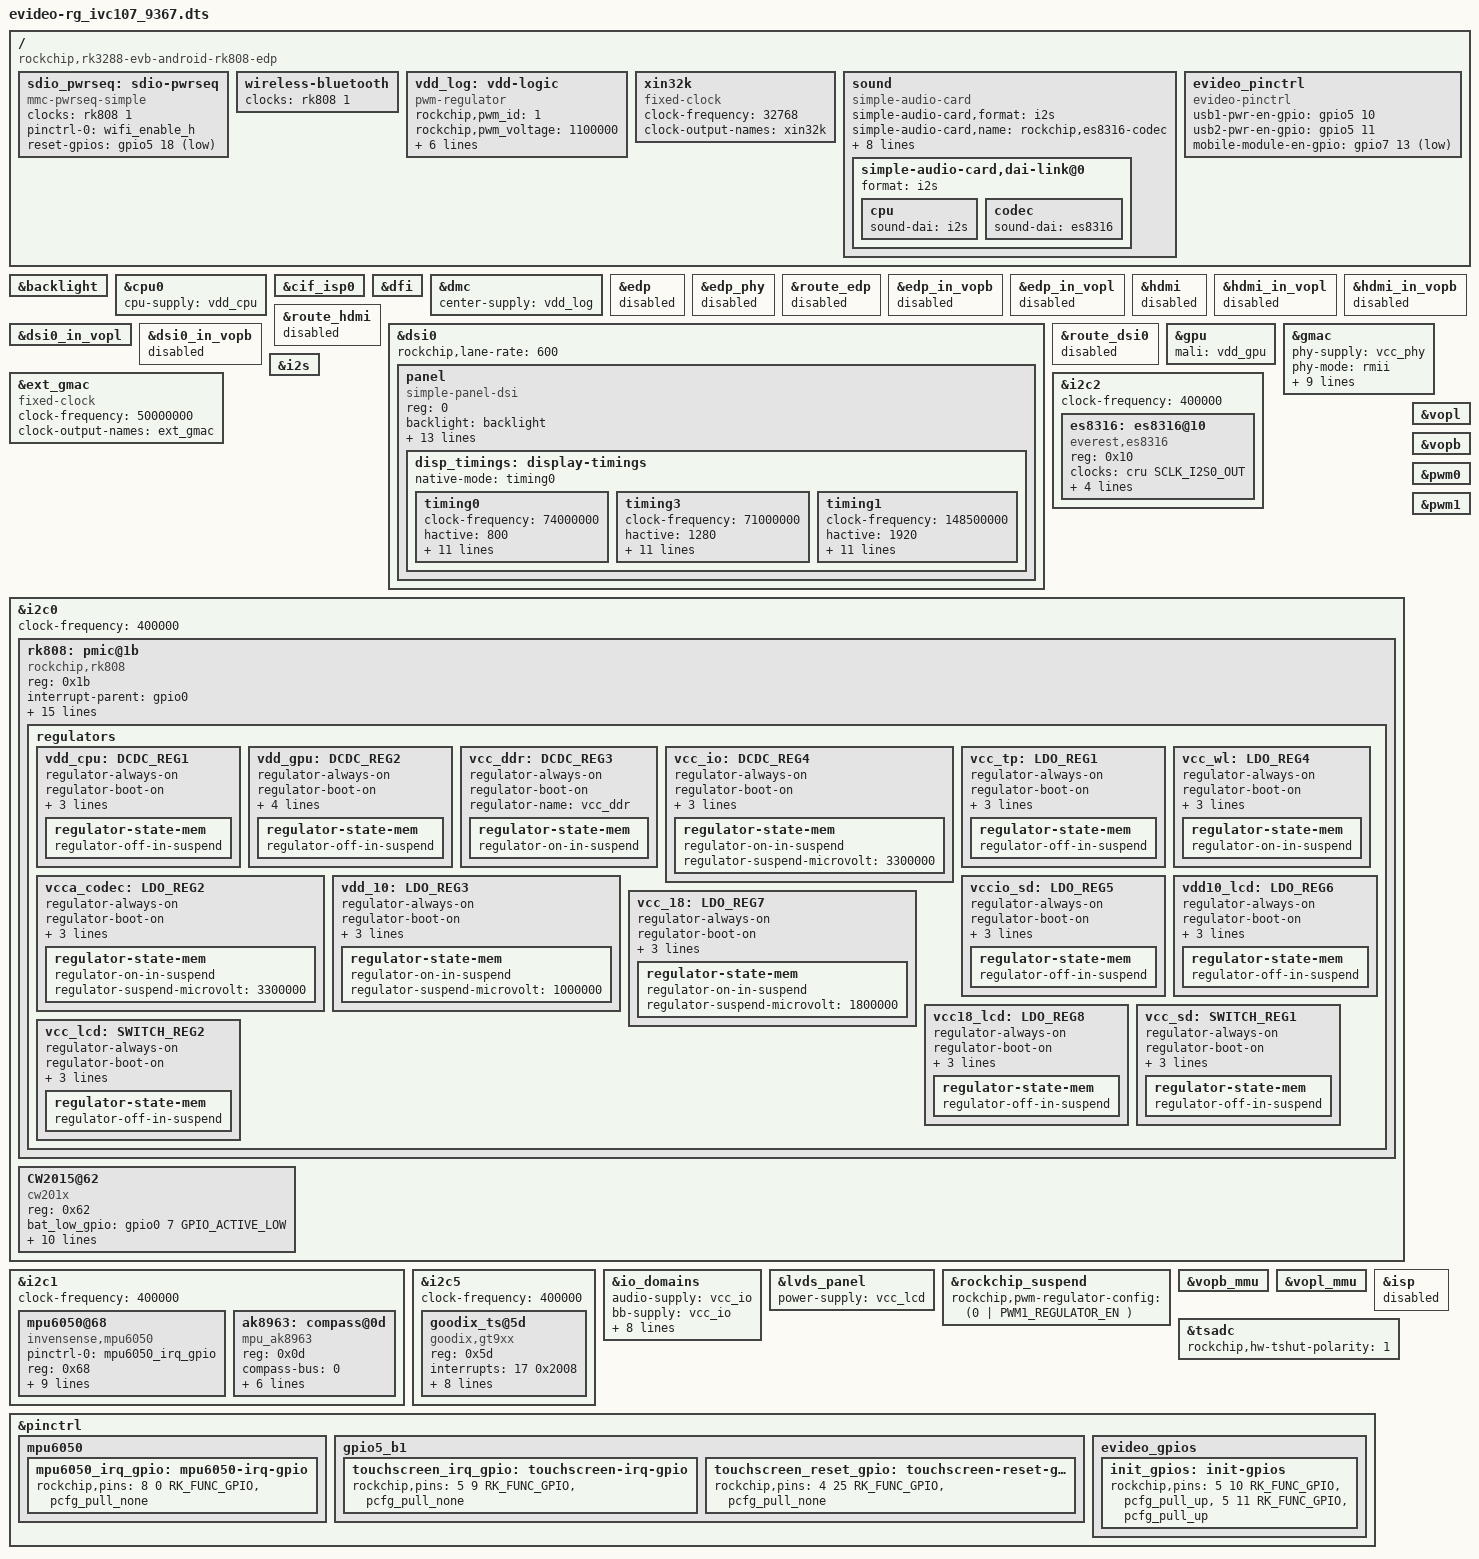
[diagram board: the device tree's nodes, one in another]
/*
 * This file is dual-licensed: you can use it either under the terms
 * of the GPL or the X11 license, at your option. Note that this dual
 * licensing only applies to this file, and not this project as a
 * whole.
 *
 *  a) This file is free software; you can redistribute it and/or
 *     modify it under the terms of the GNU General Public License as
 *     published by the Free Software Foundation; either version 2 of the
 *     License, or (at your option) any later version.
 *
 *     This file is distributed in the hope that it will be useful,
 *     but WITHOUT ANY WARRANTY; without even the implied warranty of
 *     MERCHANTABILITY or FITNESS FOR A PARTICULAR PURPOSE.  See the
 *     GNU General Public License for more details.
 *
 * Or, alternatively,
 *
 *  b) Permission is hereby granted, free of charge, to any person
 *     obtaining a copy of this software and associated documentation
 *     files (the "Software"), to deal in the Software without
 *     restriction, including without limitation the rights to use,
 *     copy, modify, merge, publish, distribute, sublicense, and/or
 *     sell copies of the Software, and to permit persons to whom the
 *     Software is furnished to do so, subject to the following
 *     conditions:
 *
 *     The above copyright notice and this permission notice shall be
 *     included in all copies or substantial portions of the Software.
 *
 *     THE SOFTWARE IS PROVIDED "AS IS", WITHOUT WARRANTY OF ANY KIND,
 *     EXPRESS OR IMPLIED, INCLUDING BUT NOT LIMITED TO THE WARRANTIES
 *     OF MERCHANTABILITY, FITNESS FOR A PARTICULAR PURPOSE AND
 *     NONINFRINGEMENT. IN NO EVENT SHALL THE AUTHORS OR COPYRIGHT
 *     HOLDERS BE LIABLE FOR ANY CLAIM, DAMAGES OR OTHER LIABILITY,
 *     WHETHER IN AN ACTION OF CONTRACT, TORT OR OTHERWISE, ARISING
 *     FROM, OUT OF OR IN CONNECTION WITH THE SOFTWARE OR THE USE OR
 *     OTHER DEALINGS IN THE SOFTWARE.
 */

/dts-v1/;
#include "rk3288-evb.dtsi"
#include "rk3288-android.dtsi"
#include <dt-bindings/pwm/pwm.h>

/ {
	compatible = "rockchip,rk3288-evb-android-rk808-edp", "rockchip,rk3288";

	sdio_pwrseq: sdio-pwrseq {
		compatible = "mmc-pwrseq-simple";
		clocks = <&rk808 1>;
		clock-names = "ext_clock";
		pinctrl-names = "default";
		pinctrl-0 = <&wifi_enable_h>;

		/*
		 * On the module itself this is one of these (depending
		 * on the actual card populated):
		 * - SDIO_RESET_L_WL_REG_ON
		 * - PDN (power down when low)
		 */
		/*reset-gpios = <&gpio5 18 GPIO_ACTIVE_LOW>;*/
        reset-gpios = <&gpio5 18 GPIO_ACTIVE_LOW>;
	};

	wireless-bluetooth {
		clocks = <&rk808 1>;
		clock-names = "ext_clock";
	};

	/delete-node/ sdmmc-regulator;

	vdd_log: vdd-logic {
		compatible = "pwm-regulator";
		rockchip,pwm_id = <1>;
		rockchip,pwm_voltage = <1100000>;
		pwms = <&pwm1 0 25000 1>;
		regulator-name = "vcc_log";
		regulator-min-microvolt = <860000>;
		regulator-max-microvolt = <1360000>;
		regulator-always-on;
		regulator-boot-on;
	};

	xin32k: xin32k {
		compatible = "fixed-clock";
		clock-frequency = <32768>;
		clock-output-names = "xin32k";
		#clock-cells = <0>;
	};


    // Microphone Jack
    sound: sound {
                compatible = "simple-audio-card";
                simple-audio-card,format = "i2s";
                simple-audio-card,name = "rockchip,es8316-codec";
                simple-audio-card,hp-det-gpio = <&gpio6 5 GPIO_ACTIVE_HIGH>;
                simple-audio-card,mic-det-gpio = <&gpio6 6 GPIO_ACTIVE_HIGH>;
                simple-audio-card,mclk-fs = <512>;
                simple-audio-card,widgets =
                        "Microphone", "Mic Jack",
                        "Headphone", "Headphone Jack";

                simple-audio-card,routing =
                        "MIC1", "Mic Jack",
                        "MIC2", "Mic Jack",
                        "Mic Jack", "micbias",
                        "Headphone Jack", "HPOL",
                        "Headphone Jack", "HPOR";


                simple-audio-card,dai-link@0 {
                        format = "i2s";
                        cpu {
                                sound-dai = <&i2s>;
                        };

                        codec {
                                sound-dai = <&es8316>;
                        };
                };

        };

    // evideo pinctrl
    evideo_pinctrl: evideo_pinctrl {
        status = "okay";
        compatible = "evideo-pinctrl";
        // pinctrl-names = "default";
        // pinctrl-0 = <&init_gpios>;

        usb1-pwr-en-gpio = <&gpio5 10 GPIO_ACTIVE_HIGH>;
        usb2-pwr-en-gpio = <&gpio5 11 GPIO_ACTIVE_HIGH>;
        mobile-module-en-gpio = <&gpio7 13 GPIO_ACTIVE_LOW>;
    };


};

&backlight {
	status = "okay";
};

&cpu0 {
	cpu-supply = <&vdd_cpu>;
};

&cif_isp0 {
	status = "okay";
};

&dfi {
	status = "okay";
};

&dmc {
    center-supply = <&vdd_log>;
	status = "okay";
};


&edp {
	status = "disabled";
};



&edp_phy {
    status = "disabled";
};

&route_edp {
	status = "disabled";
};

&edp_in_vopb {
    status = "disabled";
};

&edp_in_vopl {
    status = "disabled";
};


&hdmi {
    status = "disabled";
};

&hdmi_in_vopl {
    status = "disabled";
};

&hdmi_in_vopb {
    status = "disabled";
};

&route_hdmi {
    status = "disabled";
};

&dsi0 {
        status = "okay";
        rockchip,lane-rate = <600>;

        panel: panel {
                compatible = "simple-panel-dsi";
                reg = <0>;
                backlight = <&backlight>;
                enable-gpios = <&gpio7 3 GPIO_ACTIVE_HIGH>;
                reset-gpios = <&gpio4 0 GPIO_ACTIVE_HIGH>;
                power = <&vcc_lcd>;
                dsi,flags = <(MIPI_DSI_MODE_VIDEO | MIPI_DSI_MODE_VIDEO_BURST | MIPI_DSI_MODE_LPM)>;
                dsi,format = <MIPI_DSI_FMT_RGB888>;
                dsi,lanes = <4>;
                reset-delay-ms = <20>;
                init-delay-ms = <20>;
                enable-delay-ms = <120>;
                prepare-delay-ms = <120>;
                status = "okay";

		/*
		panel-init-sequence = [
					15 00 02 E0 00
					15 00 02 E1 93
					15 00 02 E2 65
					15 00 02 E3 F8
					15 00 02 80 03
					15 00 02 E0 01
					15 00 02 00 00
					15 00 02 01 6E
					15 00 02 03 00
					15 00 02 04 75
					15 00 02 17 00
					15 00 02 18 D7
					15 00 02 19 01
					15 00 02 1A 00
					15 00 02 1B D7
					15 00 02 1C 01
					15 00 02 1F 79
					15 00 02 20 2D
					15 00 02 21 2D
					15 00 02 22 0F
					15 00 02 37 09
					15 00 02 38 04
					15 00 02 39 00
					15 00 02 3A 01
					15 00 02 3C 70
					15 00 02 3D FF
					15 00 02 3E FF
					15 00 02 3F 7F
					15 00 02 40 06
					15 00 02 41 A0
					15 00 02 43 1E
					15 00 02 44 0D
					15 00 02 45 28
					15 00 02 4B 04
					15 00 02 55 0F
					15 00 02 56 01
					15 00 02 57 A9
					15 00 02 58 0A
					15 00 02 59 2A
					15 00 02 5A 37
					15 00 02 5B 19
					15 00 02 5D 78
					15 00 02 5E 55
					15 00 02 5F 43
					15 00 02 60 36
					15 00 02 61 31
					15 00 02 62 22
					15 00 02 63 26
					15 00 02 64 10
					15 00 02 65 29
					15 00 02 66 27
					15 00 02 67 27
					15 00 02 68 44
					15 00 02 69 32
					15 00 02 6A 3C
					15 00 02 6B 3F
					15 00 02 6C 29
					15 00 02 6D 1C
					15 00 02 6E 0D
					15 00 02 6F 02
					15 00 02 70 78
					15 00 02 71 55
					15 00 02 72 43
					15 00 02 73 36
					15 00 02 74 31
					15 00 02 75 22
					15 00 02 76 26
					15 00 02 77 10
					15 00 02 78 29
					15 00 02 79 27
					15 00 02 7A 27
					15 00 02 7B 44
					15 00 02 7C 32
					15 00 02 7D 3C
					15 00 02 7E 3F
					15 00 02 7F 29
					15 00 02 80 1C
					15 00 02 81 0D
					15 00 02 82 02
					15 00 02 E0 02
					15 00 02 00 40
					15 00 02 01 44
					15 00 02 02 46
					15 00 02 03 48
					15 00 02 04 4A
					15 00 02 05 4C
					15 00 02 06 4E
					15 00 02 07 57
					15 00 02 08 77
					15 00 02 09 55
					15 00 02 0A 50
					15 00 02 0B 55 
					15 00 02 0C 55 
					15 00 02 0D 55 
					15 00 02 0E 55 
					15 00 02 0F 55 
					15 00 02 10 55 
					15 00 02 11 55 
					15 00 02 12 55 
					15 00 02 13 52 
					15 00 02 14 55 
					15 00 02 15 55 
					15 00 02 16 41 
					15 00 02 17 45 
					15 00 02 18 47 
					15 00 02 19 49 
					15 00 02 1A 4B 
					15 00 02 1B 4D 
					15 00 02 1C 4F 
					15 00 02 1D 57 
					15 00 02 1E 77 
					15 00 02 1F 55 
					15 00 02 20 51 
					15 00 02 21 55 
					15 00 02 22 55 
					15 00 02 23 55 
					15 00 02 24 55 
					15 00 02 25 55 
					15 00 02 26 55 
					15 00 02 27 55 
					15 00 02 28 55 
					15 00 02 29 53 
					15 00 02 2A 55 
					15 00 02 2B 55 
					15 00 02 2C 11 
					15 00 02 2D 0F 
					15 00 02 2E 0D 
					15 00 02 2F 0B 
					15 00 02 30 09 
					15 00 02 31 07 
					15 00 02 32 05 
					15 00 02 33 17 
					15 00 02 34 17 
					15 00 02 35 15 
					15 00 02 36 01 
					15 00 02 37 15 
					15 00 02 38 15 
					15 00 02 39 15 
					15 00 02 3A 15 
					15 00 02 3B 15 
					15 00 02 3C 15 
					15 00 02 3D 15 
					15 00 02 3E 15 
					15 00 02 3F 13 
					15 00 02 40 15 
					15 00 02 41 15 
					15 00 02 42 10 
					15 00 02 43 0E 
					15 00 02 44 0C 
					15 00 02 45 0A 
					15 00 02 46 08 
					15 00 02 47 06 
					15 00 02 48 04 
					15 00 02 49 17 
					15 00 02 4A 17 
					15 00 02 4B 15 
					15 00 02 4C 00 
					15 00 02 4D 15 
					15 00 02 4E 15 
					15 00 02 4F 15 
					15 00 02 50 15 
					15 00 02 51 15 
					15 00 02 52 15 
					15 00 02 53 15 
					15 00 02 54 15 
					15 00 02 55 12 
					15 00 02 56 15 
					15 00 02 57 15 
					15 00 02 58 40 
					15 00 02 59 00 
					15 00 02 5A 00 
					15 00 02 5B 10 
					15 00 02 5C 06 
					15 00 02 5D 40 
					15 00 02 5E 00 
					15 00 02 5F 00 
					15 00 02 60 40 
					15 00 02 61 03 
					15 00 02 62 04 
					15 00 02 63 60 
					15 00 02 64 60 
					15 00 02 65 75 
					15 00 02 66 0C 
					15 00 02 67 B4 
					15 00 02 68 08 
					15 00 02 69 60 
					15 00 02 6A 60 
					15 00 02 6B 10 
					15 00 02 6C 00 
					15 00 02 6D 04 
					15 00 02 6E 00 
					15 00 02 6F 88 
					15 00 02 70 00 
					15 00 02 71 00 
					15 00 02 72 06 
					15 00 02 73 7B 
					15 00 02 74 00 
					15 00 02 75 BC 
					15 00 02 76 00 
					15 00 02 77 0D 
					15 00 02 78 2C 
					15 00 02 79 00 
					15 00 02 7A 00 
					15 00 02 7B 00 
					15 00 02 7C 00 
					15 00 02 7D 03 
					15 00 02 7E 7B 
					15 00 02 E0 04 
					15 00 02 09 10 
					15 00 02 0E 48 
					15 00 02 27 48 
					15 00 02 2B 2B 
					15 00 02 2E 44 
					15 00 02 2D 03 
					15 00 02 E0 05 
					15 00 02 12 72 
					15 00 02 E0 00 
					15 00 02 E6 02 
					15 00 02 E7 06 
					15 00 02 11 00 
					15 78 02 29 00 
					15 05 02 E0 03 
					15 05 02 AB 0E 
					15 05 02 E0 00 
					15 05 FF 01 29
		];
		*/
	
                //C_JD9367_CMI_8.0 Screen.
                panel-init-sequence = [
                    15 00 02 E0 00
                    15 00 02 E1 93
                    15 00 02 E2 65
                    15 00 02 E3 F8
                    15 00 02 80 03
                    15 00 02 E0 01
                    15 00 02 00 00
                    15 00 02 01 6E
                    15 00 02 03 00
                    15 00 02 04 75
                    15 00 02 17 00
                    15 00 02 18 D7
                    15 00 02 19 01
                    15 00 02 1A 00
                    15 00 02 1B D7
                    15 00 02 1C 01
                    15 00 02 1F 79
                    15 00 02 20 2D
                    15 00 02 21 2D
                    15 00 02 22 0F
                    15 00 02 37 09
                    15 00 02 38 04
                    15 00 02 39 00
                    15 00 02 3A 01
                    15 00 02 3C 70
                    15 00 02 3D FF
                    15 00 02 3E FF
                    15 00 02 3F 7F
                    15 00 02 40 06
                    15 00 02 41 A0
                    15 00 02 43 1E
                    15 00 02 44 0D
                    15 00 02 45 28
                    15 00 02 4B 04
                    15 00 02 55 0F
                    15 00 02 56 01
                    15 00 02 57 A9
                    15 00 02 58 0A
                    15 00 02 59 2A
                    15 00 02 5A 37
                    15 00 02 5B 19
                    15 00 02 5D 78
                    15 00 02 5E 55
                    15 00 02 5F 43
                    15 00 02 60 36
                    15 00 02 61 31
                    15 00 02 62 22
                    15 00 02 63 26
                    15 00 02 64 10
                    15 00 02 65 29
                    15 00 02 66 27
                    15 00 02 67 27
                    15 00 02 68 44
                    15 00 02 69 32
                    15 00 02 6A 3C
                    15 00 02 6B 3F
                    15 00 02 6C 29
                    15 00 02 6D 1C
                    15 00 02 6E 0D
                    15 00 02 6F 02
                    15 00 02 70 78
                    15 00 02 71 55
                    15 00 02 72 43
                    15 00 02 73 36
                    15 00 02 74 31
                    15 00 02 75 22
                    15 00 02 76 26
                    15 00 02 77 10
                    15 00 02 78 29
                    15 00 02 79 27
                    15 00 02 7A 27
                    15 00 02 7B 44
                    15 00 02 7C 32
                    15 00 02 7D 3C
                    15 00 02 7E 3F
                    15 00 02 7F 29
                    15 00 02 80 1C
                    15 00 02 81 0D
                    15 00 02 82 02
                    15 00 02 E0 02
                    15 00 02 00 40
                    15 00 02 01 44
                    15 00 02 02 46
                    15 00 02 03 48
                    15 00 02 04 4A
                    15 00 02 05 4C
                    15 00 02 06 4E
                    15 00 02 07 57
                    15 00 02 08 77
                    15 00 02 09 55
                    15 00 02 0A 50
                    15 00 02 0B 55
                    15 00 02 0C 55
                    15 00 02 0D 55
                    15 00 02 0E 55
                    15 00 02 0F 55
                    15 00 02 10 55
                    15 00 02 11 55
                    15 00 02 12 55
                    15 00 02 13 52
                    15 00 02 14 55
                    15 00 02 15 55
                    15 00 02 16 41
                    15 00 02 17 45
                    15 00 02 18 47
                    15 00 02 19 49
                    15 00 02 1A 4B
                    15 00 02 1B 4D
                    15 00 02 1C 4F
                    15 00 02 1D 57
                    15 00 02 1E 77
                    15 00 02 1F 55
                    15 00 02 20 51
                    15 00 02 21 55
                    15 00 02 22 55
                    15 00 02 23 55
                    15 00 02 24 55
                    15 00 02 25 55
                    15 00 02 26 55
                    15 00 02 27 55
                    15 00 02 28 55
                    15 00 02 29 53
                    15 00 02 2A 55
                    15 00 02 2B 55
                    15 00 02 2C 11
                    15 00 02 2D 0F
                    15 00 02 2E 0D
                    15 00 02 2F 0B
                    15 00 02 30 09
                    15 00 02 31 07
                    15 00 02 32 05
                    15 00 02 33 17
                    15 00 02 34 17
                    15 00 02 35 15
                    15 00 02 36 01
                    15 00 02 37 15
                    15 00 02 38 15
                    15 00 02 39 15
                    15 00 02 3A 15
                    15 00 02 3B 15
                    15 00 02 3C 15
                    15 00 02 3D 15
                    15 00 02 3E 15
                    15 00 02 3F 13
                    15 00 02 40 15
                    15 00 02 41 15
                    15 00 02 42 10
                    15 00 02 43 0E
                    15 00 02 44 0C
                    15 00 02 45 0A
                    15 00 02 46 08
                    15 00 02 47 06
                    15 00 02 48 04
                    15 00 02 49 17
                    15 00 02 4A 17
                    15 00 02 4B 15
                    15 00 02 4C 00
                    15 00 02 4D 15
                    15 00 02 4E 15
                    15 00 02 4F 15
                    15 00 02 50 15
                    15 00 02 51 15
                    15 00 02 52 15
                    15 00 02 53 15
                    15 00 02 54 15
                    15 00 02 55 12
                    15 00 02 56 15
                    15 00 02 57 15
                    15 00 02 58 40
                    15 00 02 59 00
                    15 00 02 5A 00
                    15 00 02 5B 10
                    15 00 02 5C 06
                    15 00 02 5D 40
                    15 00 02 5E 00
                    15 00 02 5F 00
                    15 00 02 60 40
                    15 00 02 61 03
                    15 00 02 62 04
                    15 00 02 63 60
                    15 00 02 64 60
                    15 00 02 65 75
                    15 00 02 66 0C
                    15 00 02 67 B4
                    15 00 02 68 08
                    15 00 02 69 60
                    15 00 02 6A 60
                    15 00 02 6B 10
                    15 00 02 6C 00
                    15 00 02 6D 04
                    15 00 02 6E 00
                    15 00 02 6F 88
                    15 00 02 70 00
                    15 00 02 71 00
                    15 00 02 72 06
                    15 00 02 73 7B
                    15 00 02 74 00
                    15 00 02 75 BC
                    15 00 02 76 00
                    15 00 02 77 0D
                    15 00 02 78 2C
                    15 00 02 79 00
                    15 00 02 7A 00
                    15 00 02 7B 00
                    15 00 02 7C 00
                    15 00 02 7D 03
                    15 00 02 7E 7B
                    15 00 02 E0 04
                    15 00 02 09 10
                    15 00 02 0E 48
                    15 00 02 27 48
                    15 00 02 2B 2B
                    15 00 02 2E 44
                    15 00 02 2D 03
                    15 00 02 E0 05
                    15 00 02 12 72
                    15 00 02 E0 00
                    15 00 02 E6 02
                    15 00 02 E7 06
                    15 00 02 11 00
                    15 78 02 29 00
                    15 05 02 E0 03
                    15 05 02 AB 0E
                    15 05 02 E0 00
                ];

		/*
		panel-init-sequence = [ 
                    15 00 02 E0 00
                    15 00 02 E1 93
                    15 00 02 E2 65
                    15 00 02 E3 F8
                    15 00 02 80 03
                    15 00 02 E0 01
                    15 00 02 00 00
                    15 00 02 01 3C
                    15 00 02 03 00
                    15 00 02 04 3C
                    15 00 02 17 00
                    15 00 02 18 F7
                    15 00 02 19 01
                    15 00 02 1A 00
                    15 00 02 1B F7
                    15 00 02 1C 01
                    15 00 02 24 F1
                    15 00 02 35 23
                    15 00 02 37 09
                    15 00 02 38 04
                    15 00 02 39 00
                    15 00 02 3A 01
                    15 00 02 3C 70
                    15 00 02 3D FF
                    15 00 02 3E FF
                    15 00 02 3F 7F
                    15 00 02 40 06
                    15 00 02 41 A0
                    15 00 02 43 1E
                    15 00 02 44 0B
                    15 00 02 45 28
                    15 00 02 55 01
                    15 00 02 57 69
                    15 00 02 59 0A
                    15 00 02 5A 2D
                    15 00 02 5B 1A
                    15 00 02 5C 15
                    15 00 02 5D 7F
                    15 00 02 5E 69
                    15 00 02 5F 59
                    15 00 02 60 4C
                    15 00 02 61 47
                    15 00 02 62 38
                    15 00 02 63 3D
                    15 00 02 64 27
                    15 00 02 65 41
                    15 00 02 66 40
                    15 00 02 67 40
                    15 00 02 68 5B
                    15 00 02 69 46
                    15 00 02 6A 49
                    15 00 02 6B 3A
                    15 00 02 6C 34
                    15 00 02 6D 25
                    15 00 02 6E 15
                    15 00 02 6F 02
                    15 00 02 70 7F
                    15 00 02 71 69
                    15 00 02 72 59
                    15 00 02 73 4C
                    15 00 02 74 47
                    15 00 02 75 38
                    15 00 02 76 3D
                    15 00 02 77 27
                    15 00 02 78 41
                    15 00 02 79 40
                    15 00 02 7A 40
                    15 00 02 7B 5B
                    15 00 02 7C 46
                    15 00 02 7D 49
                    15 00 02 7E 3A
                    15 00 02 7F 34
                    15 00 02 80 25
                    15 00 02 81 15
                    15 00 02 82 02
                    15 00 02 E0 02
                    15 00 02 00 50
                    15 00 02 01 55
                    15 00 02 02 55
                    15 00 02 03 52
                    15 00 02 04 77
                    15 00 02 05 57
                    15 00 02 06 55
                    15 00 02 07 4E
                    15 00 02 08 4C
                    15 00 02 09 55
                    15 00 02 0A 4A
                    15 00 02 0B 48
                    15 00 02 0C 55
                    15 00 02 0D 46
                    15 00 02 0E 44
                    15 00 02 0F 40
                    15 00 02 10 55
                    15 00 02 11 55
                    15 00 02 12 55
                    15 00 02 13 55
                    15 00 02 14 55
                    15 00 02 15 55
                    15 00 02 16 51
                    15 00 02 17 55
                    15 00 02 18 55
                    15 00 02 19 53
                    15 00 02 1A 77
                    15 00 02 1B 57
                    15 00 02 1C 55
                    15 00 02 1D 4F
                    15 00 02 1E 4D
                    15 00 02 1F 55
                    15 00 02 20 4B
                    15 00 02 21 49
                    15 00 02 22 55
                    15 00 02 23 47
                    15 00 02 24 45
                    15 00 02 25 41
                    15 00 02 26 55
                    15 00 02 27 55
                    15 00 02 28 55
                    15 00 02 29 55
                    15 00 02 2A 55
                    15 00 02 2B 55
                    15 00 02 2C 01
                    15 00 02 2D 15
                    15 00 02 2E 15
                    15 00 02 2F 13
                    15 00 02 30 17
                    15 00 02 31 17
                    15 00 02 32 15
                    15 00 02 33 0D
                    15 00 02 34 0F
                    15 00 02 35 15
                    15 00 02 36 05
                    15 00 02 37 07
                    15 00 02 38 15
                    15 00 02 39 09
                    15 00 02 3A 0B
                    15 00 02 3B 11
                    15 00 02 3C 15
                    15 00 02 3D 15
                    15 00 02 3E 15
                    15 00 02 3F 15
                    15 00 02 40 15
                    15 00 02 41 15
                    15 00 02 42 00
                    15 00 02 43 15
                    15 00 02 44 15
                    15 00 02 45 12
                    15 00 02 46 17
                    15 00 02 47 17
                    15 00 02 48 15
                    15 00 02 49 0C
                    15 00 02 4A 0E
                    15 00 02 4B 15
                    15 00 02 4C 04
                    15 00 02 4D 06
                    15 00 02 4E 15
                    15 00 02 4F 08
                    15 00 02 50 0A
                    15 00 02 51 10
                    15 00 02 52 15
                    15 00 02 53 15
                    15 00 02 54 15
                    15 00 02 55 15
                    15 00 02 56 15
                    15 00 02 57 15
                    15 00 02 58 40
                    15 00 02 5B 10
                    15 00 02 5C 06
                    15 00 02 5D 40
                    15 00 02 5E 00
                    15 00 02 5F 00
                    15 00 02 60 40
                    15 00 02 61 03
                    15 00 02 62 04
                    15 00 02 63 6C
                    15 00 02 64 6C
                    15 00 02 65 75
                    15 00 02 66 08
                    15 00 02 67 B4
                    15 00 02 68 08
                    15 00 02 69 6C
                    15 00 02 6A 6C
                    15 00 02 6B 0C
                    15 00 02 6D 00
                    15 00 02 6E 00
                    15 00 02 6F 88
                    15 00 02 75 BB
                    15 00 02 76 00
                    15 00 02 77 05
                    15 00 02 78 2A
                    15 00 02 E0 04
                    15 00 02 2D 03
                    15 00 02 09 11
                    15 00 02 0E 48
                    15 00 02 E0 00
                    15 78 01 11
                    15 05 01 29
                ];*/

                disp_timings: display-timings {
                        native-mode = <&timing0>;
                    
                        timing0: timing0 {
                                clock-frequency = <74000000>;
                                hactive = <800>;
                                vactive = <1280>;
                                hback-porch = <20>;
                                hfront-porch = <20>;
                                vback-porch = <10>;
                                vfront-porch = <30>;
                                hsync-len = <26>;
                                vsync-len = <4>;
                                hsync-active = <0>;
                                vsync-active = <0>;
                                de-active = <0>;
                                pixelclk-active = <0>;

                        };
			

                        timing3: timing3 {
                                clock-frequency = <71000000>;
                                hactive = <1280>;
                                vactive = <800>;
                                hback-porch = <100>;
                                hfront-porch = <18>;
                                vback-porch = <8>;
                                vfront-porch = <6>;
                                hsync-len = <10>;
                                vsync-len = <2>;
                                hsync-active = <0>;
                                vsync-active = <0>;
                                de-active = <0>;
                                pixelclk-active = <0>;
                        };

			            timing1: timing1 {
                                clock-frequency = <148500000>;
                                hactive = <1920>;
                                vactive = <1080>;
                                hback-porch = <148>;
                                hfront-porch = <88>;
                                vback-porch = <11>;
                                vfront-porch = <3>;
                                hsync-len = <32>;
                                vsync-len = <6>;
                                hsync-active = <0>;
                                vsync-active = <0>;
                                de-active = <0>;
                                pixelclk-active = <0>;

                        };
                };
        };

};

/*
&route_dsi0 {
        connect = <&vopb_out_dsi0>;
};

&route_dsi0 {
        connect = <&vopl_out_dsi0>;
};


&mipi_dphy {
    status = "okay";
};

*/





&dsi0_in_vopl {
    status = "okay";
};

&dsi0_in_vopb { 
    status = "disabled";
};

&route_dsi0 {
    status = "disabled";
};


&gpu {
	status = "okay";
	mali = <&vdd_gpu>;
};

&ext_gmac {
    compatible = "fixed-clock";
    clock-frequency = <50000000>;
    clock-output-names = "ext_gmac";
    #clock-cells = <0>;
};


&gmac {
    phy-supply = <&vcc_phy>;
    phy-mode = "rmii";
    clock_in_out = "input";
    snps,reset-gpio = <&gpio4 8 0>;
    snps,reset-active-low;
    snps,reset-delays-us = <0 10000 50000>;
    assigned-clocks = <&cru SCLK_MAC>;
    assigned-clock-parents = <&ext_gmac>;
    pinctrl-names = "default";
    pinctrl-0 = <&rmii_pins>;
    tx_delay = <0x30>;
    rx_delay = <0x30>;
    status = "okay";
};

/*
&hdmi_analog_sound {
	status = "disabled";
};
*/

&sound {
    status = "okay";
};


&i2c2 {
    status = "okay";
    clock-frequency = <400000>;

    es8316: es8316@10 {
        #sound-dai-cells = <0>;
        status = "okay";
        compatible = "everest,es8316";
        reg = <0x10>;
        clocks = <&cru SCLK_I2S0_OUT>;
        clock-names = "mclk";
        interrupt-parent = <&gpio6>;
        interrupts = <7 IRQ_TYPE_EDGE_FALLING>;
        pinctrl-names = "default";
        spk-con-gpio = <&gpio7 11 GPIO_ACTIVE_HIGH>;
        // hp-det-gpio = <&gpio6 5 GPIO_ACTIVE_HIGH>;
        
        // usb1-pwr-en-gpio = <&gpio5 10 GPIO_ACTIVE_HIGH>;
        // usb2-pwr-en-gpio = <&gpio5 11 GPIO_ACTIVE_HIGH>;
        // usb-host1-en-gpio = <&gpio7 5 GPIO_ACTIVE_LOW>;
        
        pinctrl-0 = <&i2s0_mclk>;
    };
};


&i2s {
    #sound-dai-cells = <0>;
    status = "okay";
};

&i2c0 {
	clock-frequency = <400000>;

	rk808: pmic@1b {
		compatible = "rockchip,rk808";
		reg = <0x1b>;
		interrupt-parent = <&gpio0>;
		interrupts = <4 IRQ_TYPE_LEVEL_LOW>;
		pinctrl-names = "default";
		pinctrl-0 = <&pmic_int &global_pwroff>;
		rockchip,system-power-controller;
		wakeup-source;
		#clock-cells = <1>;
		clock-output-names = "rk808-clkout1", "rk808-clkout2";

		vcc1-supply = <&vcc_sys>;
		vcc2-supply = <&vcc_sys>;
		vcc3-supply = <&vcc_sys>;
		vcc4-supply = <&vcc_sys>;
		vcc6-supply = <&vcc_sys>;
		vcc8-supply = <&vcc_io>;
		vcc9-supply = <&vcc_io>;
		vcc12-supply = <&vcc_io>;
		vddio-supply = <&vcc_io>;

		regulators {
			vdd_cpu: DCDC_REG1 {
				regulator-always-on;
				regulator-boot-on;
				regulator-min-microvolt = <750000>;
				regulator-max-microvolt = <1400000>;
				regulator-name = "vdd_arm";
				regulator-state-mem {
					regulator-off-in-suspend;
				};
			};

			vdd_gpu: DCDC_REG2 {
				regulator-always-on;
				regulator-boot-on;
				regulator-min-microvolt = <850000>;
				regulator-max-microvolt = <1250000>;
				regulator-name = "vdd_gpu";
				regulator-ramp-delay = <6000>;
				regulator-state-mem {
					regulator-off-in-suspend;
				};
			};

			vcc_ddr: DCDC_REG3 {
				regulator-always-on;
				regulator-boot-on;
				regulator-name = "vcc_ddr";
				regulator-state-mem {
					regulator-on-in-suspend;
				};
			};

			vcc_io: DCDC_REG4 {
				regulator-always-on;
				regulator-boot-on;
				regulator-min-microvolt = <3300000>;
				regulator-max-microvolt = <3300000>;
				regulator-name = "vcc_io";
				regulator-state-mem {
					regulator-on-in-suspend;
					regulator-suspend-microvolt = <3300000>;
				};
			};

			vcc_tp: LDO_REG1 {
				regulator-always-on;
				regulator-boot-on;
				regulator-min-microvolt = <3300000>;
				regulator-max-microvolt = <3300000>;
				regulator-name = "vcc_tp";
				regulator-state-mem {
					regulator-off-in-suspend;
				};
			};

			vcca_codec: LDO_REG2 {
				regulator-always-on;
				regulator-boot-on;
				regulator-min-microvolt = <3300000>;
				regulator-max-microvolt = <3300000>;
				regulator-name = "vcca_codec";
				regulator-state-mem {
					regulator-on-in-suspend;
					regulator-suspend-microvolt = <3300000>;
				};
			};

			vdd_10: LDO_REG3 {
				regulator-always-on;
				regulator-boot-on;
				regulator-min-microvolt = <1000000>;
				regulator-max-microvolt = <1000000>;
				regulator-name = "vdd_10";
				regulator-state-mem {
					regulator-on-in-suspend;
					regulator-suspend-microvolt = <1000000>;
				};
			};

			vcc_wl: LDO_REG4 {
				regulator-always-on;
				regulator-boot-on;
				regulator-min-microvolt = <1800000>;
				regulator-max-microvolt = <1800000>;
				regulator-name = "vcc_wl";
				regulator-state-mem {
					regulator-on-in-suspend;
				};
			};

			vccio_sd: LDO_REG5 {
				regulator-always-on;
				regulator-boot-on;
				regulator-min-microvolt = <1800000>;
				regulator-max-microvolt = <3300000>;
				regulator-name = "vccio_sd";
				regulator-state-mem {
					regulator-off-in-suspend;
				};
			};

			vdd10_lcd: LDO_REG6 {
				regulator-always-on;
				regulator-boot-on;
				regulator-min-microvolt = <1000000>;
				regulator-max-microvolt = <1000000>;
				regulator-name = "vdd10_lcd";
				regulator-state-mem {
					regulator-off-in-suspend;
				};
			};

			vcc_18: LDO_REG7 {
				regulator-always-on;
				regulator-boot-on;
				regulator-min-microvolt = <1800000>;
				regulator-max-microvolt = <1800000>;
				regulator-name = "vcc_18";
				regulator-state-mem {
					regulator-on-in-suspend;
					regulator-suspend-microvolt = <1800000>;
				};
			};

			vcc18_lcd: LDO_REG8 {
				regulator-always-on;
				regulator-boot-on;
				regulator-min-microvolt = <1800000>;
				regulator-max-microvolt = <1800000>;
				regulator-name = "vcc18_lcd";
				regulator-state-mem {
					regulator-off-in-suspend;
				};
			};

			vcc_sd: SWITCH_REG1 {
				regulator-always-on;
				regulator-boot-on;
				regulator-min-microvolt = <3300000>;
				regulator-max-microvolt = <3300000>;
				regulator-name = "vcc_sd";
				regulator-state-mem {
					regulator-off-in-suspend;
				};
			};

            vcc_lcd: SWITCH_REG2 {
                regulator-always-on;
                regulator-boot-on;
                regulator-min-microvolt = <3300000>;
                regulator-max-microvolt = <3300000>;
                regulator-name = "vcc_lcd";
                regulator-state-mem {
                    regulator-off-in-suspend;
                };
            };

		};
	};

	CW2015@62 {
		compatible = "cw201x";
		reg = <0x62>;
		bat_low_gpio = <&gpio0 7 GPIO_ACTIVE_LOW>;
		dc_det_gpio = <&gpio0 8 GPIO_ACTIVE_LOW>;
		chg_ok_gpio = <&gpio0 9 GPIO_ACTIVE_HIGH>;
		bat_config_info = <0x15 0x42 0x60 0x59 0x52 0x58 0x4D 0x48 0x48 0x44 0x44 0x46 0x49 0x48 0x32
			0x24 0x20 0x17 0x13 0x0F 0x19 0x3E 0x51 0x45 0x08 0x76 0x0B 0x85 0x0E 0x1C 0x2E 0x3E 0x4D 0x52 0x52
			0x57 0x3D 0x1B 0x6A 0x2D 0x25 0x43 0x52 0x87 0x8F 0x91 0x94 0x52 0x82 0x8C 0x92 0x96 0xFF 0x7B 0xBB
			0xCB 0x2F 0x7D 0x72 0xA5 0xB5 0xC1 0x46 0xAE>;
		is_dc_charge = <1>;
		is_usb_charge = <0>;
		monitor_sec = <5>;
		virtual_power = <0>;
		divider_res1 = <200>;
		divider_res2 = <200>;
	};
};

/*
&wireless-bluetooth {
    status = "disabled";
};


&wireless-wlan {
    status = "disabled";
};*/

&i2c1 {
	status = "okay";
	clock-frequency = <400000>;

	mpu6050@68 {
		compatible = "invensense,mpu6050";
		status = "okay";
		pinctrl-names = "default";
		pinctrl-0 = <&mpu6050_irq_gpio>;
		reg = <0x68>;
		irq-gpio = <&gpio8 0 IRQ_TYPE_EDGE_RISING>;
		mpu-int_config = <0x10>;
		mpu-level_shifter = <0>;
		mpu-orientation = <0 1 0 1 0 0 0 0 1>;
		orientation-x= <0>;
		orientation-y= <0>;
		orientation-z= <1>;
		support-hw-poweroff = <0>;
		mpu-debug = <1>;
	};

	ak8963:compass@0d{
		compatible = "mpu_ak8963";
		reg = <0x0d>;
		compass-bus = <0>;
		compass-adapt_num = <0>;
		compass-orientation = <1 0 0 0 1 0 0 0 1>;
		orientation-x= <0>;
		orientation-y= <0>;
		orientation-z= <1>;
		compass-debug = <1>;
		status = "okay";
	};
};

&i2c5 {
        status = "okay";
        clock-frequency = <400000>;
        
        goodix_ts@5d {
            compatible = "goodix,gt9xx";
            reg = <0x5d>;
            // interrupt-parent = <&gpio5>;
            interrupts = <17 0x2008>;
            // vdd_ana-supply = <&pm8226_l19>;
            // vcc_i2c-supply = <&pm8226_lvs1>;

            goodix,rst-gpio = <&gpio4 25 GPIO_ACTIVE_HIGH>;
            goodix,irq-gpio = <&gpio5 9 IRQ_TYPE_LEVEL_LOW>;
            pinctrl-0 = <&touchscreen_irq_gpio &touchscreen_reset_gpio>;

            goodix,cfg-group0 = [
                42 D0 02 00 05 05 75 01 01 0F 24 
                0F 64 3C 03 05 00 00 00 02 00 00 
                00 16 19 1C 14 8C 0E 0E 24 00 31 
                0D 00 00 00 83 33 1D 00 41 00 00 
                00 00 00 08 0A 00 2B 1C 3C 94 D5 
                03 08 00 00 04 93 1E 00 82 23 00 
                74 29 00 69 2F 00 5F 37 00 5F 20 
                40 60 00 F0 40 30 55 50 27 00 00 
                00 00 00 00 00 00 00 00 00 00 00 
                00 00 00 00 00 00 00 14 19 00 00 
                50 50 02 04 06 08 0A 0C 0E 10 12 
                14 16 18 1A 1C 00 00 00 00 00 00 
                00 00 00 00 00 00 00 00 00 00 1D 
                1E 1F 20 21 22 24 26 28 29 2A 1C 
                18 16 14 13 12 10 0F 0C 0A 08 06 
                04 02 00 00 00 00 00 00 00 00 00 
                00 00 00 00 00 00 00 00 9C 01];

            goodix,cfg-group2 = [
                48 D0 02 00 05 05 75 01 01 0F 24 
                0F 64 3C 03 05 00 00 00 02 00 00 
                00 16 19 1C 14 8C 0E 0E 24 00 31 
                0D 00 00 00 83 33 1D 00 41 00 00 
                3C 0A 14 08 0A 00 2B 1C 3C 94 D5 
                03 08 00 00 04 93 1E 00 82 23 00 
                74 29 00 69 2F 00 5F 37 00 5F 20 
                40 60 00 F0 40 30 55 50 27 00 00 
                00 00 00 00 00 00 00 00 00 00 00 
                00 00 00 00 00 00 00 14 19 00 00 
                50 50 02 04 06 08 0A 0C 0E 10 12 
                14 16 18 1A 1C 00 00 00 00 00 00 
                00 00 00 00 00 00 00 00 00 00 1D 
                1E 1F 20 21 22 24 26 28 29 2A 1C 
                18 16 14 13 12 10 0F 0C 0A 08 06 
                04 02 00 00 00 00 00 00 00 00 00 
                00 00 00 00 00 00 00 00 3C 01];
            

            /*
            goodix,cfg-group0 = [
                41 20 03 00 05 0A 05 00 01 08 32 05 5A 32 03 
                05 00 00 00 00 00 00 00 00 00 00 00 8E 2E 99 
                2D 2F D9 0B 00 00 00 01 03 1D 00 00 00 00 00 
                00 00 00 00 00 00 1B 5A 94 C5 02 07 00 00 04 
                00 00 00 16 00 00 00 00 00 0B 00 00 00 00 00 
                0B 00 00 00 00 00 00 00 00 00 00 00 00 00 00 
                00 00 00 00 00 00 00 00 00 00 00 00 00 00 00 
                00 00 00 00 00 00 00 17 16 15 14 11 10 0F 0E 
                0D 0C 09 08 07 06 05 04 01 00 FF FF 00 00 00 
                00 00 00 00 00 00 00 00 02 04 06 07 08 0A 0C 
                0D 0F 10 11 12 13 19 1B 1C 1E 1F 20 21 22 23 
                24 25 26 27 28 FF FF FF FF 00 00 00 00 00 00 
                00 00 00 00 C4 01];

            goodix,cfg-group2 = [
                48 D0 02 00 05 05 75 01 01 0F 24 
                0F 64 3C 03 05 00 00 00 02 00 00 
                00 16 19 1C 14 8C 0E 0E 24 00 31 
                0D 00 00 00 83 33 1D 00 41 00 00 
                3C 0A 14 08 0A 00 2B 1C 3C 94 D5 
                03 08 00 00 04 93 1E 00 82 23 00 
                74 29 00 69 2F 00 5F 37 00 5F 20 
                40 60 00 F0 40 30 55 50 27 00 00 
                00 00 00 00 00 00 00 00 00 00 00 
                00 00 00 00 00 00 00 14 19 00 00 
                50 50 02 04 06 08 0A 0C 0E 10 12 
                14 16 18 1A 1C 00 00 00 00 00 00 
                00 00 00 00 00 00 00 00 00 00 1D 
                1E 1F 20 21 22 24 26 28 29 2A 1C 
                18 16 14 13 12 10 0F 0C 0A 08 06 
                04 02 00 00 00 00 00 00 00 00 00 
                00 00 00 00 00 00 00 00 3C 01];
            */
        };
};


&io_domains {
	status = "okay";
	audio-supply = <&vcc_io>;
	bb-supply = <&vcc_io>;
	dvp-supply = <&vcc_io>;
	flash0-supply = <&vcc_18>;
	flash1-supply = <&vcc_io>;
	gpio30-supply = <&vcc_io>;
	gpio1830 = <&vcc_io>;
	lcdc-supply = <&vcc_lcd>;
	sdcard-supply = <&vccio_sd>;
	wifi-supply = <&vcc_wl>;
};

&lvds_panel {
	power-supply = <&vcc_lcd>;
};

&rockchip_suspend {
	status = "okay";
	rockchip,pwm-regulator-config = <
	(0
	| PWM1_REGULATOR_EN
	)
	>;
};


&vopb_mmu {
    status = "okay";
};

&vopl {
    status = "okay";
};

&vopb {
    status = "okay";
};


&vopl_mmu {
    status = "okay";
};


&pwm0 {
        status = "okay";
};

&pwm1 {
        status = "okay";
};

&isp {
 status = "disabled";
};


&tsadc {
    rockchip,hw-tshut-polarity = <1>; /* tshut polarity 0:LOW 1:HIGH */
};

&pinctrl {
	mpu6050 {
		mpu6050_irq_gpio: mpu6050-irq-gpio {
			rockchip,pins = <8 0 RK_FUNC_GPIO &pcfg_pull_none>;
		};
	};

    gpio5_b1 {
        touchscreen_irq_gpio: touchscreen-irq-gpio {
            rockchip,pins = <5 9 RK_FUNC_GPIO &pcfg_pull_none>;
        };
        
        touchscreen_reset_gpio: touchscreen-reset-gpio {
            rockchip,pins = <4 25 RK_FUNC_GPIO &pcfg_pull_none>;
        };
    };

    evideo_gpios {
        init_gpios: init-gpios {
            rockchip,pins = <5 10 RK_FUNC_GPIO &pcfg_pull_up>, // USB1_PWR_EN
                            <5 11 RK_FUNC_GPIO &pcfg_pull_up>; // USB2_PWR_EN
        };
    };

    
};


